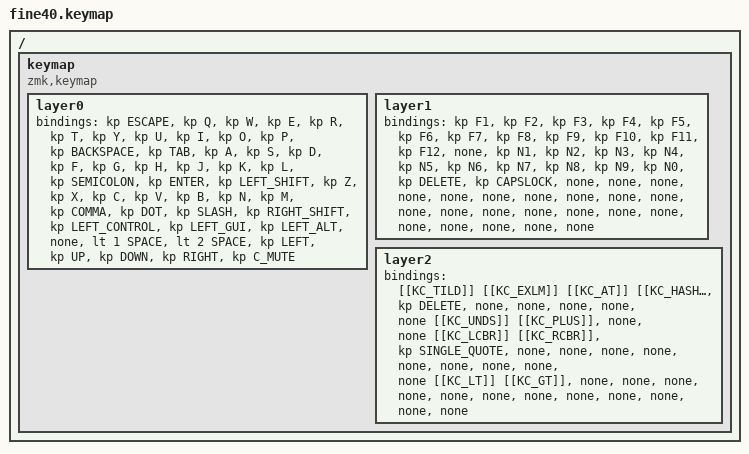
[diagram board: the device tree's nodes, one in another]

  /*
  * Copyright (c) 2020 The ZMK Contributors
  *
  * SPDX-License-Identifier: MIT
  */

  #include <behaviors.dtsi>
  #include <dt-bindings/zmk/keys.h>
  #include <dt-bindings/zmk/bt.h>
  #include <dt-bindings/zmk/ext_power.h>

  / {
    keymap {
      compatible = "zmk,keymap";
  layer0 {
          bindings = <
          &kp ESCAPE &kp Q &kp W &kp E &kp R &kp T &kp Y &kp U &kp I &kp O &kp P &kp BACKSPACE &kp TAB &kp A &kp S &kp D &kp F &kp G &kp H &kp J &kp K &kp L &kp SEMICOLON &kp ENTER &kp LEFT_SHIFT &kp Z &kp X &kp C &kp V &kp B &kp N &kp M &kp COMMA &kp DOT &kp SLASH &kp RIGHT_SHIFT &kp LEFT_CONTROL &kp LEFT_GUI &kp LEFT_ALT &none &lt 1 SPACE &lt 2 SPACE &kp LEFT &kp UP &kp DOWN &kp RIGHT &kp C_MUTE
          >;
        };layer1 {
          bindings = <
          &kp F1 &kp F2 &kp F3 &kp F4 &kp F5 &kp F6 &kp F7 &kp F8 &kp F9 &kp F10 &kp F11 &kp F12 &none &kp N1 &kp N2 &kp N3 &kp N4 &kp N5 &kp N6 &kp N7 &kp N8 &kp N9 &kp N0 &kp DELETE &kp CAPSLOCK &none &none &none &none &none &none &none &none &none &none &none &none &none &none &none &none &none &none &none &none &none &none
          >;
        };layer2 {
          bindings = <
          [[KC_TILD]] [[KC_EXLM]] [[KC_AT]] [[KC_HASH]] [[KC_DLR]] [[KC_PERC]] [[KC_CIRC]] [[KC_AMPR]] [[KC_ASTR]] [[KC_LPRN]] [[KC_RPRN]] &kp DELETE &none &none &none &none &none [[KC_UNDS]] [[KC_PLUS]] &none &none [[KC_LCBR]] [[KC_RCBR]] &kp SINGLE_QUOTE &none &none &none &none &none &none &none &none &none [[KC_LT]] [[KC_GT]] &none &none &none &none &none &none &none &none &none &none &none &none
          >;
        };
    };
  };
  
